# slm32x030 register map
Vendor: Keil; File version: 1.0.1
CPU: CM0 r2p1, little endian, no MPU, no FPU, 4 interrupt priority bits
Registers are 32-bit, read-write, reset 0x0 unless marked. A register's access mark holds for its fields unless they carry their own. Offsets are from the block's base; [hi:lo] are bit positions; {n}, {i} and the like mark numbered series.

## DBGMCU — Debugging support(DBGMCU)
Base 0x40015800
0x00 ID ro reset 0x1000095A — DBGMCU_ID
  [31:0] ID — Later Add Description
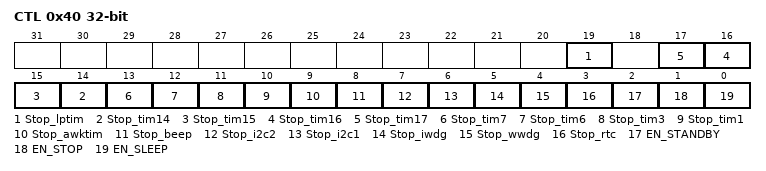
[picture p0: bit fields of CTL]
0x40 CTL — DBGMCU_CTL
  [19] Stop_lptim — Later Add Description
  [n] Stop_tim{n} (n=14..17) — Later Add Description
  [13] Stop_tim7 — Later Add Description
  [12] Stop_tim6 — Later Add Description
  [11] Stop_tim3 — Later Add Description
  [10] Stop_tim1 — Later Add Description
  [9] Stop_awktim — Later Add Description
  [8] Stop_beep — Later Add Description
  [7] Stop_i2c2 — Later Add Description
  [6] Stop_i2c1 — Later Add Description
  [5] Stop_iwdg — Later Add Description
  [4] Stop_wwdg — Later Add Description
  [3] Stop_rtc — Later Add Description
  [2] EN_STANDBY — Later Add Description
  [1] EN_STOP — Later Add Description
  [0] EN_SLEEP — Later Add Description
0x80 DBGMCU_RESERVED
  [0] SCLK_AO — Later Add Description
0xC0 DBGEN reset 0x1 — DBGMCU_DBGEN
  [0] DBGEN — Later Add Description

## LPTIM — Low power timer(LPTIM)
Base 0x40013C00
0x00 CNTVAL access not given — LPTIM_CNTVAL
  [15:0] LPT_CNT — Later Add Description
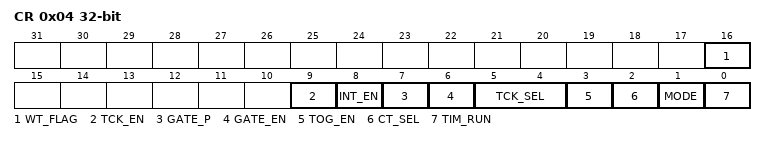
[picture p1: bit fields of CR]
0x04 CR access not given — LPTIM_CR
  [16] WT_FLAG — Later Add Description
  [9] TCK_EN — Later Add Description
  [8] INT_EN — Later Add Description
  [7] GATE_P — Later Add Description
  [6] GATE_EN — Later Add Description
  [5:4] TCK_SEL — Later Add Description
  [3] TOG_EN — Later Add Description
  [2] CT_SEL — Later Add Description
  [1] MODE — Later Add Description
  [0] TIM_RUN — Later Add Description
0x08 LOAD access not given — LPTIM_LOAD
  [15:0] LOAD — Later Add Description
0x0C INTSR access not given — LPTIM_INTSR
  [0] INTF — Later Add Description
0x10 INTCLR access not given — LPTIM_INTCLR
  [0] ICLR — Later Add Description
0x14 BGLOAD access not given — LPTIM_BGLOAD
  [15:0] BGLOAD — Later Add Description

## LPUART — Low power general-purpose asynchronous transceiver(LPUART)
Base 0x40005000
0x00 SBUF — LPUART_SBUF
  [7:0] SBUF — Later Add Description
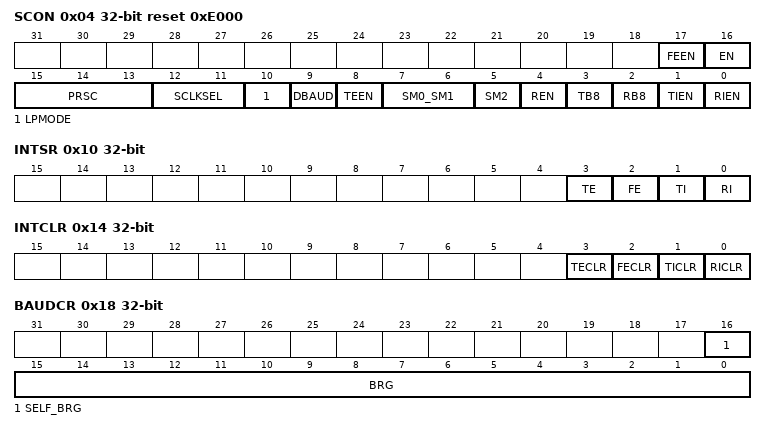
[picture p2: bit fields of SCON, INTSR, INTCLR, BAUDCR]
0x04 SCON access not given reset 0xE000 — LPUART_SCON
  [17] FEEN rw — Later Add Description
  [16] EN — Later Add Description
  [15:13] PRSC — Later Add Description
  [12:11] SCLKSEL — Later Add Description
  [10] LPMODE — Later Add Description
  [9] DBAUD — Later Add Description
  [8] TEEN — Later Add Description
  [7:6] SM0_SM1 — Later Add Description
  [5] SM2 — Later Add Description
  [4] REN — Later Add Description
  [3] TB8 — Later Add Description
  [2] RB8 — Later Add Description
  [1] TIEN — Later Add Description
  [0] RIEN — Later Add Description
0x08 SADDR access not given — LPUART_SADDR
  [7:0] SADDR — Later Add Description
0x0C SADEN access not given — LPUART_SADEN
  [7:0] SADEN — Later Add Description
0x10 INTSR access not given — LPUART_INTSR
  [3] TE — Later Add Description
  [2] FE — Later Add Description
  [1] TI — Later Add Description
  [0] RI — Later Add Description
0x14 INTCLR access not given — LPUART_INTCLR
  [3] TECLR — Later Add Description
  [2] FECLR — Later Add Description
  [1] TICLR — Later Add Description
  [0] RICLR — Later Add Description
0x18 BAUDCR access not given — LPUART_BAUDCR
  [16] SELF_BRG — Later Add Description
  [15:0] BRG — Later Add Description

## BEEP — buzzer(BEEP)
Base 0x40015400
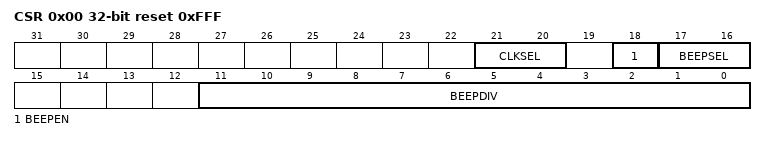
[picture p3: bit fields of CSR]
0x00 CSR access not given reset 0xFFF — BEEP_CSR
  [21:20] CLKSEL — Later Add Description
  [18] BEEPEN — Later Add Description
  [17:16] BEEPSEL — Later Add Description
  [11:0] BEEPDIV — Later Add Description

## VC — voltage comparator(VC)
Base 0x40005C00
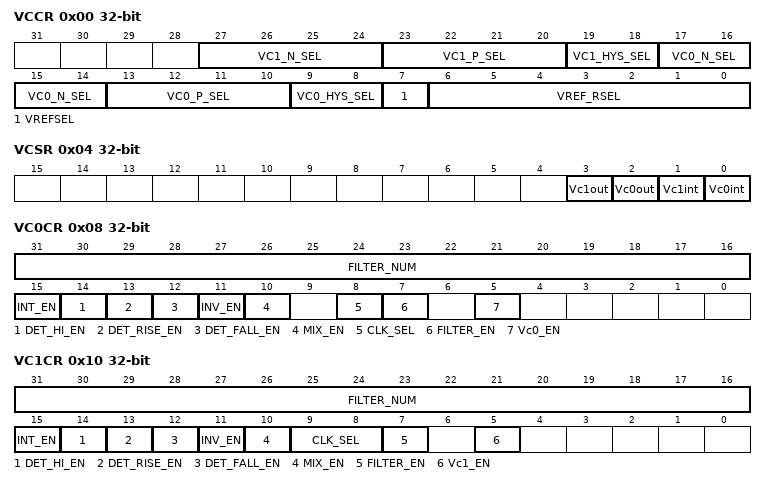
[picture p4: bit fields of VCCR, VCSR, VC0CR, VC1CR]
0x00 VCCR
  [27:24] VC1_N_SEL — Later Add Description
  [23:20] VC1_P_SEL — Later Add Description
  [19:18] VC1_HYS_SEL — Later Add Description
  [17:14] VC0_N_SEL — Later Add Description
  [13:10] VC0_P_SEL — Later Add Description
  [9:8] VC0_HYS_SEL — Later Add Description
  [7] VREFSEL — Later Add Description
  [6:0] VREF_RSEL — Later Add Description
0x04 VCSR
  [3] Vc1out — Later Add Description
  [2] Vc0out — Later Add Description
  [1] Vc1int — Later Add Description
  [0] Vc0int — Later Add Description
0x08 VC0CR — c
  [31:16] FILTER_NUM — Later Add Description
  [15] INT_EN — Later Add Description
  [14] DET_HI_EN — Later Add Description
  [13] DET_RISE_EN — Later Add Description
  [12] DET_FALL_EN — Later Add Description
  [11] INV_EN — Later Add Description
  [10] MIX_EN — Later Add Description
  [8] CLK_SEL — Later Add Description
  [7] FILTER_EN — Later Add Description
  [5] Vc0_EN — Later Add Description
0x10 VC1CR
  [31:16] FILTER_NUM — Later Add Description
  [15] INT_EN — Later Add Description
  [14] DET_HI_EN — Later Add Description
  [13] DET_RISE_EN — Later Add Description
  [12] DET_FALL_EN — Later Add Description
  [11] INV_EN — Later Add Description
  [10] MIX_EN — Later Add Description
  [9:8] CLK_SEL — Later Add Description
  [7] FILTER_EN — Later Add Description
  [5] Vc1_EN — Later Add Description

## LVD — Low voltage detector(LVD)
Base 0x40015000
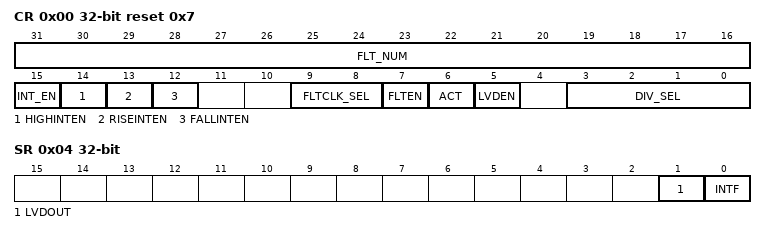
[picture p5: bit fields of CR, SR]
0x00 CR access not given reset 0x7 — LVD_CR
  [31:16] FLT_NUM — Later Add Description
  [15] INT_EN — Later Add Description
  [14] HIGHINTEN — Later Add Description
  [13] RISEINTEN — Later Add Description
  [12] FALLINTEN — Later Add Description
  [9:8] FLTCLK_SEL — Later Add Description
  [7] FLTEN — Later Add Description
  [6] ACT — Later Add Description
  [5] LVDEN — Later Add Description
  [3:0] DIV_SEL — Later Add Description
0x04 SR access not given — LVD_SR
  [1] LVDOUT — Later Add Description
  [0] INTF — Later Add Description

## TRNG — random number generator(TRNG)
Base 0x40023400
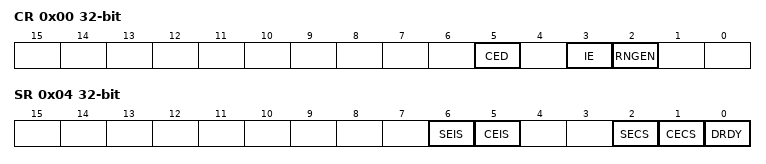
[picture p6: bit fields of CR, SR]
0x00 CR access not given — TRNG_CR
  [5] CED — Later Add Description
  [3] IE — Later Add Description
  [2] RNGEN — Later Add Description
0x04 SR access not given — TRNG_SR
  [6] SEIS — Later Add Description
  [5] CEIS — Later Add Description
  [2] SECS — Later Add Description
  [1] CECS — Later Add Description
  [0] DRDY — Later Add Description
0x08 DR access not given — TRNG_DR
  [31:0] TRNDATA — Later Add Description

## AES — Hardware accelerator(AES)
Base 0x40023800
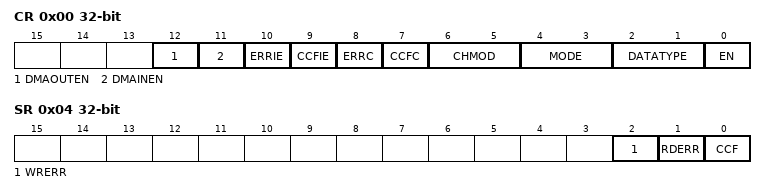
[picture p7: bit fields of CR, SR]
0x00 CR — AES_CR
  [12] DMAOUTEN — Later Add Description
  [11] DMAINEN — Later Add Description
  [10] ERRIE — Later Add Description
  [9] CCFIE — Later Add Description
  [8] ERRC — Later Add Description
  [7] CCFC — Later Add Description
  [6:5] CHMOD — Later Add Description
  [4:3] MODE — Later Add Description
  [2:1] DATATYPE — Later Add Description
  [0] EN — Later Add Description
0x04 SR — AES_SR
  [2] WRERR — Later Add Description
  [1] RDERR — Later Add Description
  [0] CCF — Later Add Description
0x08 DINR — AES_DINR
  [31:0] DINR — Later Add Description
0x0C OUTR — AES_OUTR
  [31:0] DOUTR — Later Add Description
{0x10+4i} KEYR{i} (i=0..3) — AES_KEYR{i}
  [31:0] KEYR{i} — Later Add Description
0x20 IVR0 — AES_IVR0
  [31:0] IVR0 — Later Add Description
0x24 IVR1 — AES_IVR1
  [31:0] IVR0 — Later Add Description
0x28 IVR2 — AES_IVR2
  [31:0] IVR2 — Later Add Description
0x2C IVR3 — AES_IVR3
  [31:0] IVR3 — Later Add Description

## SRAM — control(SRAM)
Base 0x40022800
0x00 CR — SRAM_CR
  [0] INTEN — Later Add Description
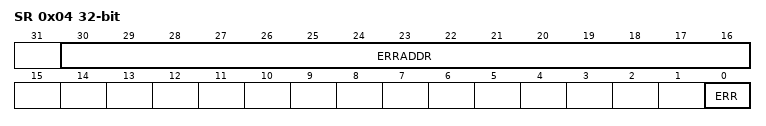
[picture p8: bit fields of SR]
0x04 SR access per field — SRAM_SR
  [30:16] ERRADDR ro — Later Add Description
  [0] ERR rw — Later Add Description

## AWK — Self-wake timer(AWK)
Base 0x40012800
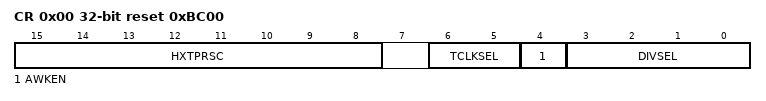
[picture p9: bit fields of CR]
0x00 CR access not given reset 0xBC00 — AWK_CR
  [15:8] HXTPRSC — Later Add Description
  [6:5] TCLKSEL — Later Add Description
  [4] AWKEN — Later Add Description
  [3:0] DIVSEL — Later Add Description
0x04 RLOAD access not given — AWK_RLOAD
  [7:0] RLDVAL — Later Add Description
0x08 SR access not given — AWK_SR
  [0] AWUF — Later Add Description
0x0C INTCLR access not given — AWK_INTCLR
  [0] INTCLR — Later Add Description
